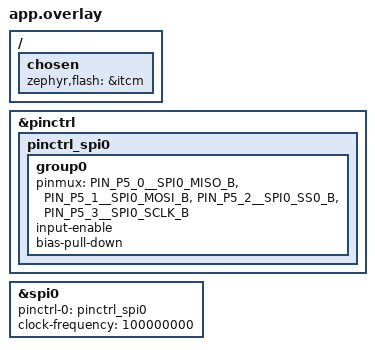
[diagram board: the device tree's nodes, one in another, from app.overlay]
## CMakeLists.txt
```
# SPDX-License-Identifier: Apache-2.0
#
# aen-spi-regcheck -- scopeless on-silicon validation of the Alif DWC_ssi SPI
# driver (zephyr/drivers/spi/spi_dw_alif.c, compatible "alif,dwc-ssi-spi") on the
# E1M-AEN801 (Ensemble E8, M55-HE), via the bench RAM-run + RAM-console flow.
#
# Plain prj.conf app (no alp_project.py board.yaml emit): the driver Kconfig
# (CONFIG_SPI_DW_ALIF, default y, depends on DT_HAS_ALIF_DWC_SSI_SPI_ENABLED) is
# sourced under CONFIG_ALP_SDK, which prj.conf sets.

cmake_minimum_required(VERSION 3.20)

find_package(Zephyr REQUIRED HINTS $ENV{ZEPHYR_BASE})
project(aen_spi_regcheck LANGUAGES C)

target_sources(app PRIVATE src/main.c)
```

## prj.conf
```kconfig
# SPDX-License-Identifier: Apache-2.0
#
# Bench RAM-run config for the E1M-AEN801 (M55-HE).

# Tier-1.5 driver Kconfigs (incl. CONFIG_SPI_DW_ALIF) are gated under ALP_SDK.
CONFIG_ALP_SDK=y

# SPI subsystem + the Alif DWC_ssi driver. CONFIG_SPI_DW_ALIF is `default y` once
# the spi0 node is enabled (DT_HAS_ALIF_DWC_SSI_SPI_ENABLED) and `select`s PINCTRL
# itself -- so we only need to turn on the SPI API here. Do NOT assign
# select-only / USE_ALIF_HAL_* symbols; the driver handles its own selects.
CONFIG_SPI=y

# Console: Alp UART console -- E1M edge UART0 (Alif UART5, P3_4/P3_5, 115200
# 8N1, NS16550), the E1M-AEN801 carrier console. The board _defconfig already
# selects it; we set it explicitly here so the example is self-describing.
CONFIG_SERIAL=y
CONFIG_CONSOLE=y
CONFIG_UART_CONSOLE=y
CONFIG_UART_INTERRUPT_DRIVEN=y
# Serial-less bench? Comment the four lines above and uncomment these to read
# 'ram_console_buf' over SWD instead:
# CONFIG_RAM_CONSOLE=y
# CONFIG_RAM_CONSOLE_BUFFER_SIZE=2048
# CONFIG_UART_CONSOLE=n
CONFIG_PRINTK=y
```

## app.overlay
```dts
/*
 * Copyright (c) 2026 Alp Lab AB
 * SPDX-License-Identifier: Apache-2.0
 *
 * aen-spi-regcheck overlay for the E1M-AEN801 (Ensemble E8, M55-HE) RAM-run.
 *
 * Enables spi0 (DesignWare DWC_ssi @ 0x48103000, driver spi_dw_alif.c) on the
 * SoC P5_x "B" pad route -- the netlist-grounded customer-facing edge SPI master
 * called out in zephyr/dts/alif/ensemble_e8_peripherals.dtsi (spi0 comment:
 * "the customer-facing edge SPI master (SoC P5_x)"):
 *
 *     P5_0  SPI0_MISO_B   (alt 4)   <- sensed input, REN must be on
 *     P5_1  SPI0_MOSI_B   (alt 4)
 *     P5_2  SPI0_SS0_B    (alt 4)   HW chip-select 0
 *     P5_3  SPI0_SCLK_B   (alt 3)
 *
 * LOOPBACK: this app uses SPI_MODE_LOOP (internal SRL loopback in the
 * controller), so NO external MOSI->MISO jumper is strictly required to validate
 * the data path -- the DWC_ssi SRL bit (CTRLR0[13]) ties TX to RX inside the
 * block. (If you instead want a PIN-level loopback, jumper P5_1 MOSI to P5_0
 * MISO and drop SPI_MODE_LOOP in main.c -- see the app's unknowns note.)
 */
#include <zephyr/dt-bindings/pinctrl/alif-ensemble-pinctrl.h>

/*
 * RAM-run: the SoC `select` puts code in XIP; retarget ROM to ITCM so the image
 * links + runs from RAM (J-Link loadbin+go, no reset). PATH-REFERENCE form
 * (&itcm) -- the phandle-array form makes FLASH_SIZE=0 and overflows the link.
 */
/ {
	chosen {
		zephyr,flash = &itcm;
		/delete-property/ zephyr,code-partition;
	};
};

&pinctrl {
	pinctrl_spi0: pinctrl_spi0 {
		group0 {
			pinmux = <PIN_P5_0__SPI0_MISO_B>,
				 <PIN_P5_1__SPI0_MOSI_B>,
				 <PIN_P5_2__SPI0_SS0_B>,
				 <PIN_P5_3__SPI0_SCLK_B>;
			/*
			 * SPI pad config, following the bench-validated I2C lesson
			 * (aen-eeprom-manifest, 2026-06-15) and Alif's reference
			 * pinctrl convention (read-enable=1 + driver-state-control=2):
			 *   input-enable   -> pad REN (bit16): the controller MUST be
			 *                     able to SENSE MISO or it samples nothing
			 *                     back. Required on any sensed pad (MISO).
			 *                     Set on the whole group; harmless on the
			 *                     driven pads (MOSI/SCLK/SS).
			 *   bias-pull-down -> upstream pinctrl_soc.h encodes the pad DSC
			 *                     field as DSC=2 from bias-pull-down, which
			 *                     is the value Alif's reference uses. Do NOT
			 *                     "correct" to bias-pull-up (DSC=1 = the dead
			 *                     bus seen on I2C).
			 */
			input-enable;
			bias-pull-down;
		};
	};
};

&spi0 {
	status = "okay";
	pinctrl-0 = <&pinctrl_spi0>;
	pinctrl-names = "default";
	/*
	 * HW chip-select 0 (SS0_B on P5_2): no cs-gpios, so the driver uses the
	 * controller SER register. The transfer below targets slave 0.
	 */

	/*
	 * Give the SPI driver a non-zero input-clock frequency.
	 *
	 * WHY THIS IS HERE (bench finding, not cosmetic): spi_dw_configure() reads
	 * info->clock_frequency.  spi_dw_alif.c PREFERS the SPI node's own
	 * `clock-frequency` (the alp-sdk-owned alif,dwc-ssi-spi binding declares
	 * it); only when absent does it fall back to clock_control_configure() --
	 * which the upstream alif clockctrl driver implements as NO-OP (-ENOSYS) ->
	 * spi_dw_configure() turns that into -EINVAL and ABORTS before programming a
	 * single register.  Setting it on the SPI node makes the driver use this
	 * value verbatim for the BAUDR divider.
	 *
	 * NOTE: this property lives on &spi0, NOT on &clockctrl -- the alif,clockctrl
	 * binding does not declare clock-frequency (placing it there is a hard DT
	 * error), and the driver reads it from the SPI node anyway.
	 *
	 * 100 MHz is a PLACEHOLDER (mirrors the UTIMER clock-frequency convention);
	 * it only scales the BAUDR divider, NOT the CTRLR0 programming the strict
	 * PASS gate checks.  Confirm the real SPI input clock vs the Alif TRM and
	 * override.
	 */
	clock-frequency = <100000000>;
};
```

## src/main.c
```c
/*
 * Copyright (c) 2026 Alp Lab AB
 * SPDX-License-Identifier: Apache-2.0
 *
 * aen-spi-regcheck -- scopeless on-silicon validation of the Alif DWC_ssi SPI
 * driver (zephyr/drivers/spi/spi_dw_alif.c, compatible "alif,dwc-ssi-spi",
 * spi0 @ 0x48103000) on the E1M-AEN801 (Ensemble E8, M55-HE), via the bench
 * RAM-run + RAM-console flow.
 *
 * We cannot see the SPI pins on this bench (no scope, app UART not on USB). So
 * we validate by driving the standard Zephyr spi_transceive() API and then doing
 * a REGISTER READBACK of the controller's CTRLR0 / SSIENR / BAUDR / SR.
 *
 * The transfer is configured as an INTERNAL LOOPBACK (SPI_MODE_LOOP -> the
 * DWC_ssi SRL bit, CTRLR0[13]): the controller ties its own TX shift-register to
 * its RX shift-register, so a full-duplex transceive echoes TX bytes back into
 * the RX buffer with NO external wire. That gives us a real data check on this
 * scopeless bench. (For a PIN-level loopback instead, jumper P5_1 MOSI -> P5_0
 * MISO and clear SPI_MODE_LOOP -- see the readback/unknowns notes.)
 *
 * Two independent confirmations, exactly like aen-pwm-utimer-regcheck:
 *   1. This firmware drives the API, prints the tx/rx bytes + the four control
 *      registers it reads back, plus a single RESULT PASS/FAIL line, to the RAM
 *      console (read 'ram_console_buf' over J-Link mem8, ASCII-decode).
 *   2. The human re-reads the SAME absolute addresses over J-Link mem32 (see the
 *      readback plan) -- so a driver that only PRINTS the right thing is caught.
 *
 * CTRLR0 expected value derivation (clock-INDEPENDENT, the strict PASS gate):
 * word size 8, SPI mode 0, master, loopback, dwc_ssi layout. From
 * spi_dw_configure() + transceive() in spi_dw_alif.c:
 *   - DFS (max_xfer_size default 16 -> DW_SPI_CTRLR0_DFS_16(8) = 8-1) = 0x7  (bits[3:0])
 *   - master + dwc_ssi -> DWC_SSI_SPI_IS_MST_BIT = BIT(31)                   = 0x80000000
 *   - mode 0 -> no SCPOL(bit9)/SCPH(bit8)
 *   - SPI_MODE_LOOP -> DWC_SSI_SPI_CTRLR0_SRL = BIT(13)                      = 0x00002000
 *   - TMOD: tx+rx bufs both present -> DW_SPI_CTRLR0_TMOD_TX_RX = 0 (bits[11:10]=00)
 *   - SSTE not set (slv-slct-toggle absent)
 *   => CTRLR0 == 0x80002007
 */

#include <stdint.h>

#include <zephyr/kernel.h>
#include <zephyr/device.h>
#include <zephyr/devicetree.h>
#include <zephyr/drivers/spi.h>
#include <zephyr/sys/printk.h>

#define SPI_NODE DT_NODELABEL(spi0)

/* Absolute reg base straight from the dtsi reg = <0x48103000 0x1000>, pulled
 * from devicetree so this stays correct if the node ever moves. */
#define SPI_BASE ((uint32_t)DT_REG_ADDR(SPI_NODE))

/* DWC_ssi register offsets -- VERBATIM from spi_dw_alif_regs.h. */
#define OFF_CTRLR0 0x00U
#define OFF_CTRLR1 0x04U
#define OFF_SSIENR 0x08U
#define OFF_BAUDR  0x14U
#define OFF_SR     0x28U

/* Expected CTRLR0 after configure for 8-bit, mode-0, master, loopback (see the
 * file header derivation). Clock-independent. */
#define EXP_CTRLR0 0x80002007U

/* SR bits (spi_dw_alif.h): bit0 BUSY, bit1 TFNF (tx fifo not full),
 * bit3 RFNE (rx fifo not empty). After completed() the controller is disabled
 * and idle, so we expect BUSY=0. */
#define SR_BUSY_BIT 0U

/* BAUDR is clk_freq / requested-freq. With the overlay's clock-frequency=100MHz
 * and a 1 MHz transfer, expect 100 (0x64). Clock-rate is a bench unknown, so
 * BAUDR is REPORTED, not part of the strict PASS gate. */
#define TEST_FREQ_HZ      1000000U
#define EXP_BAUDR_AT_100M 100U /* 100e6 / 1e6 */

static inline uint32_t rd(uint32_t base, uint32_t off)
{
	return *(volatile uint32_t *)(base + off);
}

int main(void)
{
	const struct device *spi = DEVICE_DT_GET(SPI_NODE);

	printk("\n=== aen-spi-regcheck ===\n");
	printk("spi node   : %s\n", DT_NODE_FULL_NAME(SPI_NODE));
	printk("spi_base   : 0x%08x\n", SPI_BASE);

	if (!device_is_ready(spi)) {
		printk("RESULT FAIL: spi device not ready (init/pinctrl/clock failed)\n");
		return 0;
	}

	/* 8-bit, MSB-first, SPI mode 0, master, INTERNAL loopback (SRL). */
	/* No .cs: no cs-gpios, controller SER drives SS (HW SS0 on P5_2); the
	 * field zero-initializes to that already. */
	struct spi_config cfg = {
		.frequency = TEST_FREQ_HZ,
		.operation = SPI_OP_MODE_MASTER | SPI_TRANSFER_MSB | SPI_WORD_SET(8) | SPI_MODE_LOOP,
		.slave     = 0, /* HW SS0 (SS0_B on P5_2) */
	};

	uint8_t tx[4] = { 0xA5, 0x5A, 0xC3, 0x3C };
	uint8_t rx[4] = { 0, 0, 0, 0 };

	const struct spi_buf     txb    = { .buf = tx, .len = sizeof(tx) };
	const struct spi_buf     rxb    = { .buf = rx, .len = sizeof(rx) };
	const struct spi_buf_set tx_set = { .buffers = &txb, .count = 1 };
	const struct spi_buf_set rx_set = { .buffers = &rxb, .count = 1 };

	printk("tx bytes   : %02x %02x %02x %02x\n", tx[0], tx[1], tx[2], tx[3]);
	printk("freq=%u Hz, ws=8, mode=0, master, loopback (SRL)\n", TEST_FREQ_HZ);

	int rc = spi_transceive(spi, &cfg, &tx_set, &rx_set);

	printk("spi_transceive rc = %d\n", rc);
	printk("rx bytes   : %02x %02x %02x %02x\n", rx[0], rx[1], rx[2], rx[3]);

	/*
	 * Register readback. spi_dw_alif's completed() disables the controller
	 * (clears SSIENR) at the end of a transfer, so:
	 *   - CTRLR0 retains the last-programmed value (the configure value) -- the
	 *     decisive, clock-independent evidence the driver programmed the IP.
	 *   - SSIENR reads 0 (controller disabled / idle after completion) -- expected.
	 *   - SR.BUSY reads 0 (idle).
	 *   - BAUDR retains the computed divider (reported, clock-dependent).
	 */
	uint32_t ctrlr0 = rd(SPI_BASE, OFF_CTRLR0);
	uint32_t ctrlr1 = rd(SPI_BASE, OFF_CTRLR1);
	uint32_t ssienr = rd(SPI_BASE, OFF_SSIENR);
	uint32_t baudr  = rd(SPI_BASE, OFF_BAUDR);
	uint32_t sr     = rd(SPI_BASE, OFF_SR);

	printk("-- readback --\n");
	printk("CTRLR0  0x%08x = 0x%08x (exp 0x%08x)\n", SPI_BASE + OFF_CTRLR0, ctrlr0, EXP_CTRLR0);
	printk("CTRLR1  0x%08x = 0x%08x (NDF; full-duplex path writes 0)\n",
	       SPI_BASE + OFF_CTRLR1,
	       ctrlr1);
	printk("SSIENR  0x%08x = 0x%08x (exp 0x0 after completion: ctrl disabled)\n",
	       SPI_BASE + OFF_SSIENR,
	       ssienr);
	printk("BAUDR   0x%08x = 0x%08x (exp %u @100MHz src; clk-rate is a bench unknown)\n",
	       SPI_BASE + OFF_BAUDR,
	       baudr,
	       EXP_BAUDR_AT_100M);
	printk("SR      0x%08x = 0x%08x (bit0 BUSY exp 0)\n", SPI_BASE + OFF_SR, sr);

	/* Loopback data check: with SRL set, rx must echo tx exactly. */
	bool data_ok = (rx[0] == tx[0]) && (rx[1] == tx[1]) && (rx[2] == tx[2]) && (rx[3] == tx[3]);

	/*
	 * PASS gate:
	 *   - spi_transceive returned 0 (no controller/clock error),
	 *   - CTRLR0 programmed exactly as derived (clock-independent),
	 *   - controller is idle (SR.BUSY clear),
	 *   - internal-loopback echo matched (real data path through the IP).
	 * BAUDR is reported only (clock-rate is a bench unknown), and BAUDR != 0 is
	 * folded in as a sanity check that the divider was actually written.
	 */
	bool ok = true;

	ok &= (rc == 0);
	ok &= (ctrlr0 == EXP_CTRLR0);
	ok &= ((sr & (1U << SR_BUSY_BIT)) == 0U);
	ok &= (baudr != 0U);
	ok &= data_ok;

	if (ok) {
		printk("RESULT PASS: spi0 CTRLR0=0x%08x baudr=%u, transceive rc=0, "
		       "loopback echo OK (rx==tx)\n",
		       ctrlr0,
		       baudr);
	} else {
		printk("RESULT FAIL: rc=%d ctrlr0=0x%08x(exp 0x%08x) "
		       "busy=%u baudr=%u loopback=%s\n",
		       rc,
		       ctrlr0,
		       EXP_CTRLR0,
		       (unsigned)(sr & 0x1U),
		       baudr,
		       data_ok ? "OK" : "MISMATCH");
	}

	return 0;
}
```
